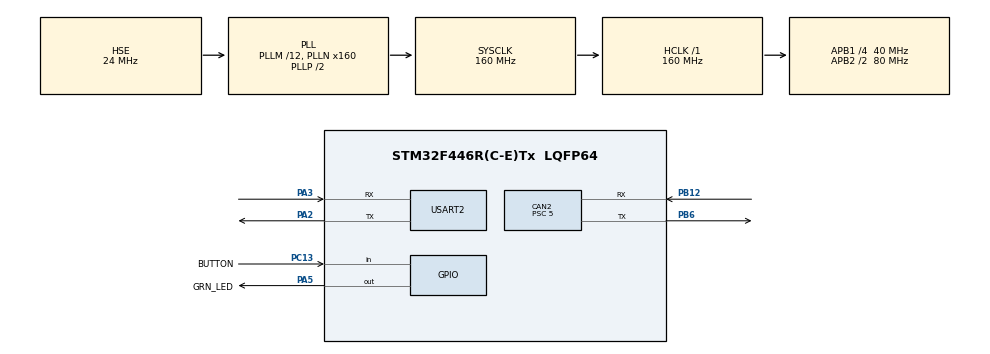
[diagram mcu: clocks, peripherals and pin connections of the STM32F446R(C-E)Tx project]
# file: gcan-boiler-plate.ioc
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CAN2.BS1=CAN_BS1_6TQ
CAN2.CalculateBaudRate=1000000
CAN2.CalculateTimeBit=1000
CAN2.CalculateTimeQuantum=125.0
CAN2.Prescaler=5
FREERTOS.Tasks01=main_task,0,512,task_MainTask,Default,NULL,Dynamic,NULL,NULL;buffer_handling,1,256,task_BufferHandling,Default,NULL,Dynamic,NULL,NULL
FREERTOS.configMINIMAL_STACK_SIZE=256
Mcu.Family=STM32F4
Mcu.Name=STM32F446R(C-E)Tx
Mcu.Package=LQFP64
NVIC.CAN2_RX0_IRQn=true\:5\:0\:false\:false\:true\:true\:true\:true\:true
NVIC.CAN2_RX1_IRQn=true\:5\:0\:false\:false\:true\:true\:true\:true\:true
NVIC.CAN2_TX_IRQn=true\:5\:0\:false\:false\:true\:true\:true\:true\:true
NVIC.PriorityGroup=NVIC_PRIORITYGROUP_4
NVIC.TIM6_DAC_IRQn=true\:15\:0\:false\:false\:true\:false\:false\:true\:true
NVIC.TimeBase=TIM6_DAC_IRQn
NVIC.TimeBaseIP=TIM6
PA2.Mode=Asynchronous
PA2.Signal=USART2_TX
PA3.Mode=Asynchronous
PA3.Signal=USART2_RX
PA5.GPIO_Label=GRN_LED
PA5.Signal=GPIO_Output
PB12.Mode=CAN_Activate
PB12.Signal=CAN2_RX
PB6.Mode=CAN_Activate
PB6.Signal=CAN2_TX
PC13.GPIO_Label=BUTTON
PC13.Signal=GPIO_Input
PH0-OSC_IN.Mode=HSE-External-Clock-Source
PH0-OSC_IN.Signal=RCC_OSC_IN
PH1-OSC_OUT.Mode=HSE-External-Clock-Source
PH1-OSC_OUT.Signal=RCC_OSC_OUT
ProjectManager.HeapSize=0x200
ProjectManager.StackSize=0x400
ProjectManager.TargetToolchain=STM32CubeIDE
RCC.AHBFreq_Value=160000000
RCC.APB1CLKDivider=RCC_HCLK_DIV4
RCC.APB1Freq_Value=40000000
RCC.APB1TimFreq_Value=80000000
RCC.APB2CLKDivider=RCC_HCLK_DIV2
RCC.APB2Freq_Value=80000000
RCC.APB2TimFreq_Value=160000000
RCC.CortexFreq_Value=160000000
RCC.HCLKFreq_Value=160000000
RCC.HSE_VALUE=24000000
RCC.PLLM=12
RCC.PLLN=160
RCC.PLLSourceVirtual=RCC_PLLSOURCE_HSE
RCC.SYSCLKFreq_VALUE=160000000
RCC.SYSCLKSource=RCC_SYSCLKSOURCE_PLLCLK
RCC.USBFreq_Value=160000000
RCC.VCOOutputFreq_Value=320000000
USART2.VirtualMode=VM_ASYNC
VP_FREERTOS_VS_CMSIS_V1.Mode=CMSIS_V1
VP_SYS_VS_tim6.Mode=TIM6
board=custom

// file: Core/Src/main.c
/* USER CODE BEGIN Header */
/**
  ******************************************************************************
  * @file           : main.c
  * @brief          : Main program body
  ******************************************************************************
  * @attention
  *
  * Copyright (c) 2022 STMicroelectronics.
  * All rights reserved.
  *
  * This software is licensed under terms that can be found in the LICENSE file
  * in the root directory of this software component.
  * If no LICENSE file comes with this software, it is provided AS-IS.
  *
  ******************************************************************************
  */
/* USER CODE END Header */
#include "main.h"
#include "cmsis_os.h"

/* USER CODE BEGIN Includes */
#include "GopherCAN_devboard_example.h"

/* USER CODE END Includes */

CAN_HandleTypeDef hcan2;

UART_HandleTypeDef huart2;

osThreadId main_taskHandle;
osThreadId buffer_handlingHandle;

void SystemClock_Config(void);
static void MX_GPIO_Init(void);
static void MX_USART2_UART_Init(void);
static void MX_CAN2_Init(void);
void task_MainTask(void const * argument);
void task_BufferHandling(void const * argument);

/* USER CODE BEGIN 0 */
#ifdef __GNUC__
#define PUTCHAR_PROTOTYPE int __io_putchar(int ch)
#else
#define PUTCHAR_PROTOTYPE int fputc(int ch, FILE *f)
#endif

PUTCHAR_PROTOTYPE
{
  HAL_UART_Transmit(&huart2, (uint8_t *)&ch, 1, HAL_MAX_DELAY);
  return ch;
}
/* USER CODE END 0 */

int main(void)
{

  /* MCU Configuration--------------------------------------------------------*/

  /* Reset of all peripherals, Initializes the Flash interface and the Systick. */
  HAL_Init();

  /* Configure the system clock */
  SystemClock_Config();

  /* Initialize all configured peripherals */
  MX_GPIO_Init();
  MX_USART2_UART_Init();
  MX_CAN2_Init();
  /* USER CODE BEGIN 2 */

  init(&hcan2);

  /* USER CODE END 2 */

  /* Create the thread(s) */
  /* definition and creation of main_task */
  osThreadDef(main_task, task_MainTask, osPriorityNormal, 0, 512);
  main_taskHandle = osThreadCreate(osThread(main_task), NULL);

  /* definition and creation of buffer_handling */
  osThreadDef(buffer_handling, task_BufferHandling, osPriorityAboveNormal, 0, 256);
  buffer_handlingHandle = osThreadCreate(osThread(buffer_handling), NULL);

  /* Start scheduler */
  osKernelStart();

  /* We should never get here as control is now taken by the scheduler */
  /* Infinite loop */
  while (1)
  {

  }
}

void SystemClock_Config(void)
{
  RCC_OscInitTypeDef RCC_OscInitStruct = {0};
  RCC_ClkInitTypeDef RCC_ClkInitStruct = {0};

  /** Configure the main internal regulator output voltage
  */
  __HAL_RCC_PWR_CLK_ENABLE();
  __HAL_PWR_VOLTAGESCALING_CONFIG(PWR_REGULATOR_VOLTAGE_SCALE1);

  /** Initializes the RCC Oscillators according to the specified parameters
  * in the RCC_OscInitTypeDef structure.
  */
  RCC_OscInitStruct.OscillatorType = RCC_OSCILLATORTYPE_HSE;
  RCC_OscInitStruct.HSEState = RCC_HSE_BYPASS;
  RCC_OscInitStruct.PLL.PLLState = RCC_PLL_ON;
  RCC_OscInitStruct.PLL.PLLSource = RCC_PLLSOURCE_HSE;
  RCC_OscInitStruct.PLL.PLLM = 12;
  RCC_OscInitStruct.PLL.PLLN = 160;
  RCC_OscInitStruct.PLL.PLLP = RCC_PLLP_DIV2;
  RCC_OscInitStruct.PLL.PLLQ = 2;
  RCC_OscInitStruct.PLL.PLLR = 2;
  if (HAL_RCC_OscConfig(&RCC_OscInitStruct) != HAL_OK)
  {
    Error_Handler();
  }

  /** Initializes the CPU, AHB and APB buses clocks
  */
  RCC_ClkInitStruct.ClockType = RCC_CLOCKTYPE_HCLK|RCC_CLOCKTYPE_SYSCLK
                              |RCC_CLOCKTYPE_PCLK1|RCC_CLOCKTYPE_PCLK2;
  RCC_ClkInitStruct.SYSCLKSource = RCC_SYSCLKSOURCE_PLLCLK;
  RCC_ClkInitStruct.AHBCLKDivider = RCC_SYSCLK_DIV1;
  RCC_ClkInitStruct.APB1CLKDivider = RCC_HCLK_DIV4;
  RCC_ClkInitStruct.APB2CLKDivider = RCC_HCLK_DIV2;

  if (HAL_RCC_ClockConfig(&RCC_ClkInitStruct, FLASH_LATENCY_5) != HAL_OK)
  {
    Error_Handler();
  }
}

static void MX_CAN2_Init(void)
{

  hcan2.Instance = CAN2;
  hcan2.Init.Prescaler = 5;
  hcan2.Init.Mode = CAN_MODE_NORMAL;
  hcan2.Init.SyncJumpWidth = CAN_SJW_1TQ;
  hcan2.Init.TimeSeg1 = CAN_BS1_6TQ;
  hcan2.Init.TimeSeg2 = CAN_BS2_1TQ;
  hcan2.Init.TimeTriggeredMode = DISABLE;
  hcan2.Init.AutoBusOff = DISABLE;
  hcan2.Init.AutoWakeUp = DISABLE;
  hcan2.Init.AutoRetransmission = DISABLE;
  hcan2.Init.ReceiveFifoLocked = DISABLE;
  hcan2.Init.TransmitFifoPriority = DISABLE;
  if (HAL_CAN_Init(&hcan2) != HAL_OK)
  {
    Error_Handler();
  }

}

static void MX_USART2_UART_Init(void)
{

  huart2.Instance = USART2;
  huart2.Init.BaudRate = 115200;
  huart2.Init.WordLength = UART_WORDLENGTH_8B;
  huart2.Init.StopBits = UART_STOPBITS_1;
  huart2.Init.Parity = UART_PARITY_NONE;
  huart2.Init.Mode = UART_MODE_TX_RX;
  huart2.Init.HwFlowCtl = UART_HWCONTROL_NONE;
  huart2.Init.OverSampling = UART_OVERSAMPLING_16;
  if (HAL_UART_Init(&huart2) != HAL_OK)
  {
    Error_Handler();
  }

}

static void MX_GPIO_Init(void)
{
  GPIO_InitTypeDef GPIO_InitStruct = {0};

  /* GPIO Ports Clock Enable */
  __HAL_RCC_GPIOC_CLK_ENABLE();
  __HAL_RCC_GPIOH_CLK_ENABLE();
  __HAL_RCC_GPIOA_CLK_ENABLE();
  __HAL_RCC_GPIOB_CLK_ENABLE();

  /*Configure GPIO pin Output Level */
  HAL_GPIO_WritePin(GRN_LED_GPIO_Port, GRN_LED_Pin, GPIO_PIN_RESET);

  /*Configure GPIO pin : BUTTON_Pin */
  GPIO_InitStruct.Pin = BUTTON_Pin;
  GPIO_InitStruct.Mode = GPIO_MODE_INPUT;
  GPIO_InitStruct.Pull = GPIO_NOPULL;
  HAL_GPIO_Init(BUTTON_GPIO_Port, &GPIO_InitStruct);

  /*Configure GPIO pin : GRN_LED_Pin */
  GPIO_InitStruct.Pin = GRN_LED_Pin;
  GPIO_InitStruct.Mode = GPIO_MODE_OUTPUT_PP;
  GPIO_InitStruct.Pull = GPIO_NOPULL;
  GPIO_InitStruct.Speed = GPIO_SPEED_FREQ_LOW;
  HAL_GPIO_Init(GRN_LED_GPIO_Port, &GPIO_InitStruct);

}

void task_MainTask(void const * argument)
{
  /* USER CODE BEGIN 5 */
  /* Infinite loop */
  for(;;)
  {
	  main_loop();
    osDelay(1);
  }
  /* USER CODE END 5 */
}

void task_BufferHandling(void const * argument)
{
  /* USER CODE BEGIN task_BufferHandling */
  /* Infinite loop */
  for(;;)
  {
	  can_buffer_handling_loop();
    osDelay(1);
  }
  /* USER CODE END task_BufferHandling */
}

void HAL_TIM_PeriodElapsedCallback(TIM_HandleTypeDef *htim)
{
  if (htim->Instance == TIM6) {
    HAL_IncTick();
  }
}

void Error_Handler(void)
{
  __disable_irq();
  while (1)
  {
  }
}
